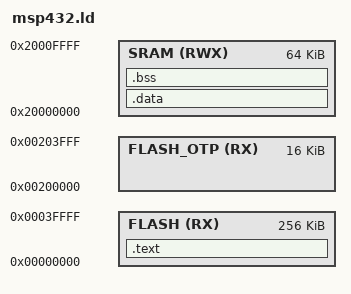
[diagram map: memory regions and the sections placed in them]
/*
 * Linker configuration file for MSP432.
 *
 * Copyright (c) 2016, Sultan Qasim Khan
 * All rights reserved.
 *
 * Redistribution and use in source and binary forms, with or without
 * modification, are permitted provided that the following conditions are met:
 *
 * 1. Redistributions of source code must retain the above copyright notice, this
 *    list of conditions and the following disclaimer.
 * 2. Redistributions in binary form must reproduce the above copyright notice,
 *    this list of conditions and the following disclaimer in the documentation
 *    and/or other materials provided with the distribution.
 *
 * THIS SOFTWARE IS PROVIDED BY THE COPYRIGHT HOLDERS AND CONTRIBUTORS "AS IS" AND
 * ANY EXPRESS OR IMPLIED WARRANTIES, INCLUDING, BUT NOT LIMITED TO, THE IMPLIED
 * WARRANTIES OF MERCHANTABILITY AND FITNESS FOR A PARTICULAR PURPOSE ARE
 * DISCLAIMED. IN NO EVENT SHALL THE COPYRIGHT OWNER OR CONTRIBUTORS BE LIABLE FOR
 * ANY DIRECT, INDIRECT, INCIDENTAL, SPECIAL, EXEMPLARY, OR CONSEQUENTIAL DAMAGES
 * (INCLUDING, BUT NOT LIMITED TO, PROCUREMENT OF SUBSTITUTE GOODS OR SERVICES;
 * LOSS OF USE, DATA, OR PROFITS; OR BUSINESS INTERRUPTION) HOWEVER CAUSED AND
 * ON ANY THEORY OF LIABILITY, WHETHER IN CONTRACT, STRICT LIABILITY, OR TORT
 * (INCLUDING NEGLIGENCE OR OTHERWISE) ARISING IN ANY WAY OUT OF THE USE OF THIS
 * SOFTWARE, EVEN IF ADVISED OF THE POSSIBILITY OF SUCH DAMAGE.
 */

_stack_size = 2K;

MEMORY
{
    FLASH                 (RX) : ORIGIN = 0x00000000, LENGTH = 0x00040000
    FLASH_OTP             (RX) : ORIGIN = 0x00200000, LENGTH = 0x00004000
    SRAM                  (RWX): ORIGIN = 0x20000000, LENGTH = 0x00010000
}

SECTIONS
{
    .text :
    {
        _text = .;
        KEEP(*(.isr_vector))
        *(.text*)
        *(.rodata*)
        _etext = .;
    } > FLASH

    .data : AT(ADDR(.text) + SIZEOF(.text))
    {
        _data = .;
        *(vtable)
        *(.data*)
        _edata = .;
    } > SRAM

    .bss :
    {
        _bss = .;
        *(.bss*)
        *(COMMON)
        _ebss = .;
    } > SRAM

    _heap_bottom = .;
    _heap_top = ORIGIN(SRAM) + LENGTH(SRAM) - _stack_size;

    _stack_bottom = _heap_top;
    _stack_top = ORIGIN(SRAM) + LENGTH(SRAM);
}
